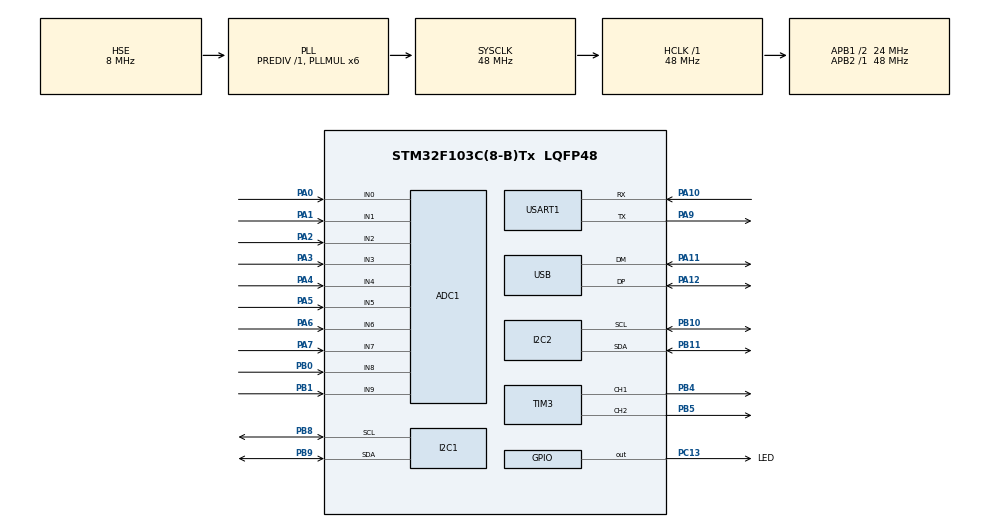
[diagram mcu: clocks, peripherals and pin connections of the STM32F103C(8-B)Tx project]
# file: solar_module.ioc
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ADC1.Channel-0\#ChannelRegularConversion=ADC_CHANNEL_0
ADC1.Channel-2\#ChannelRegularConversion=ADC_CHANNEL_1
ADC1.ContinuousConvMode=DISABLE
ADC1.DataAlign=ADC_DATAALIGN_RIGHT
ADC1.DiscontinuousConvMode=DISABLE
ADC1.EnableAnalogWatchDog=false
ADC1.EnableRegularConversion=ENABLE
ADC1.ExternalTrigConv=ADC_SOFTWARE_START
ADC1.InjNumberOfConversion=0
ADC1.NbrOfConversion=2
ADC1.NbrOfConversionFlag=1
ADC1.Rank-0\#ChannelRegularConversion=1
ADC1.Rank-2\#ChannelRegularConversion=2
ADC1.SamplingTime-0\#ChannelRegularConversion=ADC_SAMPLETIME_55CYCLES_5
ADC1.SamplingTime-2\#ChannelRegularConversion=ADC_SAMPLETIME_55CYCLES_5
ADC1.ScanConvMode=ADC_SCAN_ENABLE
ADC1.master=1
Dma.ADC1.0.Direction=DMA_PERIPH_TO_MEMORY
Dma.ADC1.0.Instance=DMA1_Channel1
Dma.ADC1.0.MemDataAlignment=DMA_MDATAALIGN_HALFWORD
Dma.ADC1.0.MemInc=DMA_MINC_ENABLE
Dma.ADC1.0.Mode=DMA_NORMAL
Dma.ADC1.0.PeriphDataAlignment=DMA_PDATAALIGN_HALFWORD
Dma.ADC1.0.PeriphInc=DMA_PINC_DISABLE
Dma.ADC1.0.Priority=DMA_PRIORITY_LOW
Dma.Request0=ADC1
Mcu.Family=STM32F1
Mcu.Name=STM32F103C(8-B)Tx
Mcu.Package=LQFP48
NVIC.DMA1_Channel1_IRQn=true\:0\:0\:false\:false\:true\:false
NVIC.PriorityGroup=NVIC_PRIORITYGROUP_4
NVIC.USB_LP_CAN1_RX0_IRQn=true\:0\:0\:false\:false\:true\:false
PA0-WKUP.Signal=ADCx_IN0
PA1.Signal=ADCx_IN1
PA10.Mode=Asynchronous
PA10.Signal=USART1_RX
PA11.Mode=Device
PA11.Signal=USB_DM
PA12.Mode=Device
PA12.Signal=USB_DP
PA13.Mode=Serial_Wire
PA13.Signal=SYS_JTMS-SWDIO
PA14.Mode=Serial_Wire
PA14.Signal=SYS_JTCK-SWCLK
PA2.Signal=ADCx_IN2
PA3.Signal=ADCx_IN3
PA4.Signal=ADCx_IN4
PA5.Signal=ADCx_IN5
PA6.Signal=ADCx_IN6
PA7.Signal=ADCx_IN7
PA9.Mode=Asynchronous
PA9.Signal=USART1_TX
PB0.Signal=ADCx_IN8
PB1.Signal=ADCx_IN9
PB10.Mode=I2C
PB10.Signal=I2C2_SCL
PB11.Mode=I2C
PB11.Signal=I2C2_SDA
PB4.Signal=S_TIM3_CH1
PB5.Signal=S_TIM3_CH2
PB8.Mode=I2C
PB8.Signal=I2C1_SCL
PB9.Mode=I2C
PB9.Signal=I2C1_SDA
PC13-TAMPER-RTC.GPIO_Label=LED
PC13-TAMPER-RTC.GPIO_ModeDefaultOutputPP=GPIO_MODE_OUTPUT_PP
PC13-TAMPER-RTC.GPIO_Speed=GPIO_SPEED_FREQ_LOW
PC13-TAMPER-RTC.PinState=GPIO_PIN_RESET
PC13-TAMPER-RTC.Signal=GPIO_Output
PD0-OSC_IN.Mode=HSE-External-Oscillator
PD0-OSC_IN.Signal=RCC_OSC_IN
PD1-OSC_OUT.Mode=HSE-External-Oscillator
PD1-OSC_OUT.Signal=RCC_OSC_OUT
ProjectManager.HeapSize=0x200
ProjectManager.StackSize=0x400
ProjectManager.TargetToolchain=TrueSTUDIO
RCC.ADCPresc=RCC_ADCPCLK2_DIV4
RCC.AHBFreq_Value=48000000
RCC.APB1CLKDivider=RCC_HCLK_DIV2
RCC.APB1Freq_Value=24000000
RCC.APB1TimFreq_Value=48000000
RCC.APB2Freq_Value=48000000
RCC.APB2TimFreq_Value=48000000
RCC.HCLKFreq_Value=48000000
RCC.PLLMUL=RCC_PLL_MUL6
RCC.PLLSourceVirtual=RCC_PLLSOURCE_HSE
RCC.SYSCLKFreq_VALUE=48000000
RCC.SYSCLKSource=RCC_SYSCLKSOURCE_PLLCLK
RCC.USBFreq_Value=48000000
SH.ADCx_IN0.0=ADC1_IN0,IN0
SH.ADCx_IN1.0=ADC1_IN1,IN1
SH.ADCx_IN2.0=ADC1_IN2,IN2
SH.ADCx_IN3.0=ADC1_IN3,IN3
SH.ADCx_IN4.0=ADC1_IN4,IN4
SH.ADCx_IN5.0=ADC1_IN5,IN5
SH.ADCx_IN6.0=ADC1_IN6,IN6
SH.ADCx_IN7.0=ADC1_IN7,IN7
SH.ADCx_IN8.0=ADC1_IN8,IN8
SH.ADCx_IN9.0=ADC1_IN9,IN9
SH.S_TIM3_CH1.0=TIM3_CH1,PWM Generation1 CH1
SH.S_TIM3_CH2.0=TIM3_CH2,PWM Generation2 CH2
TIM3.Channel-PWM\ Generation1\ CH1=TIM_CHANNEL_1
TIM3.Channel-PWM\ Generation2\ CH2=TIM_CHANNEL_2
USART1.VirtualMode=VM_ASYNC
USB.ep0_mps=DEP0CTL_MPS_64
USB_DEVICE.CLASS_NAME_FS=CDC
USB_DEVICE.VirtualMode=Cdc
USB_DEVICE.VirtualModeFS=Cdc_FS
VP_USB_DEVICE_VS_USB_DEVICE_CDC_FS.Mode=CDC_FS
board=solar_module

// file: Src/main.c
/**
  ******************************************************************************
  * @file           : main.c
  * @brief          : Main program body
  ******************************************************************************
  * This notice applies to any and all portions of this file
  * that are not between comment pairs USER CODE BEGIN and
  * USER CODE END. Other portions of this file, whether
  * inserted by the user or by software development tools
  * are owned by their respective copyright owners.
  *
  * Copyright (c) 2018 STMicroelectronics International N.V.
  * All rights reserved.
  *
  * Redistribution and use in source and binary forms, with or without
  * modification, are permitted, provided that the following conditions are met:
  *
  * 1. Redistribution of source code must retain the above copyright notice,
  *    this list of conditions and the following disclaimer.
  * 2. Redistributions in binary form must reproduce the above copyright notice,
  *    this list of conditions and the following disclaimer in the documentation
  *    and/or other materials provided with the distribution.
  * 3. Neither the name of STMicroelectronics nor the names of other
  *    contributors to this software may be used to endorse or promote products
  *    derived from this software without specific written permission.
  * 4. This software, including modifications and/or derivative works of this
  *    software, must execute solely and exclusively on microcontroller or
  *    microprocessor devices manufactured by or for STMicroelectronics.
  * 5. Redistribution and use of this software other than as permitted under
  *    this license is void and will automatically terminate your rights under
  *    this license.
  *
  * THIS SOFTWARE IS PROVIDED BY STMICROELECTRONICS AND CONTRIBUTORS "AS IS"
  * AND ANY EXPRESS, IMPLIED OR STATUTORY WARRANTIES, INCLUDING, BUT NOT
  * LIMITED TO, THE IMPLIED WARRANTIES OF MERCHANTABILITY, FITNESS FOR A
  * PARTICULAR PURPOSE AND NON-INFRINGEMENT OF THIRD PARTY INTELLECTUAL PROPERTY
  * RIGHTS ARE DISCLAIMED TO THE FULLEST EXTENT PERMITTED BY LAW. IN NO EVENT
  * SHALL STMICROELECTRONICS OR CONTRIBUTORS BE LIABLE FOR ANY DIRECT, INDIRECT,
  * INCIDENTAL, SPECIAL, EXEMPLARY, OR CONSEQUENTIAL DAMAGES (INCLUDING, BUT NOT
  * LIMITED TO, PROCUREMENT OF SUBSTITUTE GOODS OR SERVICES; LOSS OF USE, DATA,
  * OR PROFITS; OR BUSINESS INTERRUPTION) HOWEVER CAUSED AND ON ANY THEORY OF
  * LIABILITY, WHETHER IN CONTRACT, STRICT LIABILITY, OR TORT (INCLUDING
  * NEGLIGENCE OR OTHERWISE) ARISING IN ANY WAY OUT OF THE USE OF THIS SOFTWARE,
  * EVEN IF ADVISED OF THE POSSIBILITY OF SUCH DAMAGE.
  *
  ******************************************************************************
  */
#include "main.h"
#include "stm32f1xx_hal.h"
#include "usb_device.h"

/* USER CODE BEGIN Includes */
#include "usbd_cdc_if.h"
/* USER CODE END Includes */

ADC_HandleTypeDef hadc1;
DMA_HandleTypeDef hdma_adc1;

I2C_HandleTypeDef hi2c1;
I2C_HandleTypeDef hi2c2;

TIM_HandleTypeDef htim3;

UART_HandleTypeDef huart1;

/* USER CODE BEGIN PV */
/* Private variables ---------------------------------------------------------*/
volatile int numcalls = 0;

/* USER CODE END PV */

void SystemClock_Config(void);
static void MX_GPIO_Init(void);
static void MX_DMA_Init(void);
static void MX_ADC1_Init(void);
static void MX_I2C1_Init(void);
static void MX_I2C2_Init(void);
static void MX_TIM3_Init(void);
static void MX_USART1_UART_Init(void);

void HAL_TIM_MspPostInit(TIM_HandleTypeDef *htim);

/* USER CODE BEGIN PFP */
/* Private function prototypes -----------------------------------------------*/

/* USER CODE END PFP */

int main(void)
{

  /* MCU Configuration----------------------------------------------------------*/

  /* Reset of all peripherals, Initializes the Flash interface and the Systick. */
  HAL_Init();

  /* Configure the system clock */
  SystemClock_Config();

  /* Initialize all configured peripherals */
  MX_GPIO_Init();
  MX_DMA_Init();
  MX_ADC1_Init();
  MX_I2C1_Init();
  MX_I2C2_Init();
  MX_TIM3_Init();
  MX_USART1_UART_Init();
  MX_USB_DEVICE_Init();
  /* USER CODE BEGIN 2 */
  uint8_t buf[100];
  int16_t dma_buffer[2];
  /* USER CODE END 2 */

  /* Infinite loop */
  /* USER CODE BEGIN WHILE */
  while (1)
  {
	  int len = sprintf((char*)buf, "Interrupts: %i\tADC0: %i\tADC1: %i\n", numcalls, dma_buffer[0], dma_buffer[1]);
	  CDC_Transmit_FS(buf, len);
	  HAL_GPIO_TogglePin(LED_GPIO_Port, LED_Pin);
	  numcalls = 0;
	  HAL_ADC_Start_DMA(&hadc1, (uint32_t*)dma_buffer, 2);
	  HAL_Delay(1000);
  /* USER CODE END WHILE */

  }

}

void SystemClock_Config(void)
{

  RCC_OscInitTypeDef RCC_OscInitStruct;
  RCC_ClkInitTypeDef RCC_ClkInitStruct;
  RCC_PeriphCLKInitTypeDef PeriphClkInit;

    /**Initializes the CPU, AHB and APB busses clocks
    */
  RCC_OscInitStruct.OscillatorType = RCC_OSCILLATORTYPE_HSE;
  RCC_OscInitStruct.HSEState = RCC_HSE_ON;
  RCC_OscInitStruct.HSEPredivValue = RCC_HSE_PREDIV_DIV1;
  RCC_OscInitStruct.HSIState = RCC_HSI_ON;
  RCC_OscInitStruct.PLL.PLLState = RCC_PLL_ON;
  RCC_OscInitStruct.PLL.PLLSource = RCC_PLLSOURCE_HSE;
  RCC_OscInitStruct.PLL.PLLMUL = RCC_PLL_MUL6;
  if (HAL_RCC_OscConfig(&RCC_OscInitStruct) != HAL_OK)
  {
    _Error_Handler(__FILE__, __LINE__);
  }

    /**Initializes the CPU, AHB and APB busses clocks
    */
  RCC_ClkInitStruct.ClockType = RCC_CLOCKTYPE_HCLK|RCC_CLOCKTYPE_SYSCLK
                              |RCC_CLOCKTYPE_PCLK1|RCC_CLOCKTYPE_PCLK2;
  RCC_ClkInitStruct.SYSCLKSource = RCC_SYSCLKSOURCE_PLLCLK;
  RCC_ClkInitStruct.AHBCLKDivider = RCC_SYSCLK_DIV1;
  RCC_ClkInitStruct.APB1CLKDivider = RCC_HCLK_DIV2;
  RCC_ClkInitStruct.APB2CLKDivider = RCC_HCLK_DIV1;

  if (HAL_RCC_ClockConfig(&RCC_ClkInitStruct, FLASH_LATENCY_1) != HAL_OK)
  {
    _Error_Handler(__FILE__, __LINE__);
  }

  PeriphClkInit.PeriphClockSelection = RCC_PERIPHCLK_ADC|RCC_PERIPHCLK_USB;
  PeriphClkInit.AdcClockSelection = RCC_ADCPCLK2_DIV4;
  PeriphClkInit.UsbClockSelection = RCC_USBCLKSOURCE_PLL;
  if (HAL_RCCEx_PeriphCLKConfig(&PeriphClkInit) != HAL_OK)
  {
    _Error_Handler(__FILE__, __LINE__);
  }

    /**Configure the Systick interrupt time
    */
  HAL_SYSTICK_Config(HAL_RCC_GetHCLKFreq()/1000);

    /**Configure the Systick
    */
  HAL_SYSTICK_CLKSourceConfig(SYSTICK_CLKSOURCE_HCLK);

  /* SysTick_IRQn interrupt configuration */
  HAL_NVIC_SetPriority(SysTick_IRQn, 0, 0);
}

/* ADC1 init function */
static void MX_ADC1_Init(void)
{

  ADC_ChannelConfTypeDef sConfig;

    /**Common config
    */
  hadc1.Instance = ADC1;
  hadc1.Init.ScanConvMode = ADC_SCAN_ENABLE;
  hadc1.Init.ContinuousConvMode = DISABLE;
  hadc1.Init.DiscontinuousConvMode = DISABLE;
  hadc1.Init.ExternalTrigConv = ADC_SOFTWARE_START;
  hadc1.Init.DataAlign = ADC_DATAALIGN_RIGHT;
  hadc1.Init.NbrOfConversion = 2;
  if (HAL_ADC_Init(&hadc1) != HAL_OK)
  {
    _Error_Handler(__FILE__, __LINE__);
  }

    /**Configure Regular Channel
    */
  sConfig.Channel = ADC_CHANNEL_0;
  sConfig.Rank = ADC_REGULAR_RANK_1;
  sConfig.SamplingTime = ADC_SAMPLETIME_55CYCLES_5;
  if (HAL_ADC_ConfigChannel(&hadc1, &sConfig) != HAL_OK)
  {
    _Error_Handler(__FILE__, __LINE__);
  }

    /**Configure Regular Channel
    */
  sConfig.Channel = ADC_CHANNEL_1;
  sConfig.Rank = ADC_REGULAR_RANK_2;
  if (HAL_ADC_ConfigChannel(&hadc1, &sConfig) != HAL_OK)
  {
    _Error_Handler(__FILE__, __LINE__);
  }

}

/* I2C1 init function */
static void MX_I2C1_Init(void)
{

  hi2c1.Instance = I2C1;
  hi2c1.Init.ClockSpeed = 100000;
  hi2c1.Init.DutyCycle = I2C_DUTYCYCLE_2;
  hi2c1.Init.OwnAddress1 = 0;
  hi2c1.Init.AddressingMode = I2C_ADDRESSINGMODE_7BIT;
  hi2c1.Init.DualAddressMode = I2C_DUALADDRESS_DISABLE;
  hi2c1.Init.OwnAddress2 = 0;
  hi2c1.Init.GeneralCallMode = I2C_GENERALCALL_DISABLE;
  hi2c1.Init.NoStretchMode = I2C_NOSTRETCH_DISABLE;
  if (HAL_I2C_Init(&hi2c1) != HAL_OK)
  {
    _Error_Handler(__FILE__, __LINE__);
  }

}

/* I2C2 init function */
static void MX_I2C2_Init(void)
{

  hi2c2.Instance = I2C2;
  hi2c2.Init.ClockSpeed = 100000;
  hi2c2.Init.DutyCycle = I2C_DUTYCYCLE_2;
  hi2c2.Init.OwnAddress1 = 0;
  hi2c2.Init.AddressingMode = I2C_ADDRESSINGMODE_7BIT;
  hi2c2.Init.DualAddressMode = I2C_DUALADDRESS_DISABLE;
  hi2c2.Init.OwnAddress2 = 0;
  hi2c2.Init.GeneralCallMode = I2C_GENERALCALL_DISABLE;
  hi2c2.Init.NoStretchMode = I2C_NOSTRETCH_DISABLE;
  if (HAL_I2C_Init(&hi2c2) != HAL_OK)
  {
    _Error_Handler(__FILE__, __LINE__);
  }

}

/* TIM3 init function */
static void MX_TIM3_Init(void)
{

  TIM_MasterConfigTypeDef sMasterConfig;
  TIM_OC_InitTypeDef sConfigOC;

  htim3.Instance = TIM3;
  htim3.Init.Prescaler = 0;
  htim3.Init.CounterMode = TIM_COUNTERMODE_UP;
  htim3.Init.Period = 0;
  htim3.Init.ClockDivision = TIM_CLOCKDIVISION_DIV1;
  htim3.Init.AutoReloadPreload = TIM_AUTORELOAD_PRELOAD_DISABLE;
  if (HAL_TIM_PWM_Init(&htim3) != HAL_OK)
  {
    _Error_Handler(__FILE__, __LINE__);
  }

  sMasterConfig.MasterOutputTrigger = TIM_TRGO_RESET;
  sMasterConfig.MasterSlaveMode = TIM_MASTERSLAVEMODE_DISABLE;
  if (HAL_TIMEx_MasterConfigSynchronization(&htim3, &sMasterConfig) != HAL_OK)
  {
    _Error_Handler(__FILE__, __LINE__);
  }

  sConfigOC.OCMode = TIM_OCMODE_PWM1;
  sConfigOC.Pulse = 0;
  sConfigOC.OCPolarity = TIM_OCPOLARITY_HIGH;
  sConfigOC.OCFastMode = TIM_OCFAST_DISABLE;
  if (HAL_TIM_PWM_ConfigChannel(&htim3, &sConfigOC, TIM_CHANNEL_1) != HAL_OK)
  {
    _Error_Handler(__FILE__, __LINE__);
  }

  if (HAL_TIM_PWM_ConfigChannel(&htim3, &sConfigOC, TIM_CHANNEL_2) != HAL_OK)
  {
    _Error_Handler(__FILE__, __LINE__);
  }

  HAL_TIM_MspPostInit(&htim3);

}

/* USART1 init function */
static void MX_USART1_UART_Init(void)
{

  huart1.Instance = USART1;
  huart1.Init.BaudRate = 115200;
  huart1.Init.WordLength = UART_WORDLENGTH_8B;
  huart1.Init.StopBits = UART_STOPBITS_1;
  huart1.Init.Parity = UART_PARITY_NONE;
  huart1.Init.Mode = UART_MODE_TX_RX;
  huart1.Init.HwFlowCtl = UART_HWCONTROL_NONE;
  huart1.Init.OverSampling = UART_OVERSAMPLING_16;
  if (HAL_UART_Init(&huart1) != HAL_OK)
  {
    _Error_Handler(__FILE__, __LINE__);
  }

}

static void MX_DMA_Init(void)
{
  /* DMA controller clock enable */
  __HAL_RCC_DMA1_CLK_ENABLE();

  /* DMA interrupt init */
  /* DMA1_Channel1_IRQn interrupt configuration */
  HAL_NVIC_SetPriority(DMA1_Channel1_IRQn, 0, 0);
  HAL_NVIC_EnableIRQ(DMA1_Channel1_IRQn);

}

/** Configure pins as
        * Analog
        * Input
        * Output
        * EVENT_OUT
        * EXTI
*/
static void MX_GPIO_Init(void)
{

  GPIO_InitTypeDef GPIO_InitStruct;

  /* GPIO Ports Clock Enable */
  __HAL_RCC_GPIOC_CLK_ENABLE();
  __HAL_RCC_GPIOD_CLK_ENABLE();
  __HAL_RCC_GPIOA_CLK_ENABLE();
  __HAL_RCC_GPIOB_CLK_ENABLE();

  /*Configure GPIO pin Output Level */
  HAL_GPIO_WritePin(LED_GPIO_Port, LED_Pin, GPIO_PIN_RESET);

  /*Configure GPIO pin : LED_Pin */
  GPIO_InitStruct.Pin = LED_Pin;
  GPIO_InitStruct.Mode = GPIO_MODE_OUTPUT_PP;
  GPIO_InitStruct.Speed = GPIO_SPEED_FREQ_LOW;
  HAL_GPIO_Init(LED_GPIO_Port, &GPIO_InitStruct);

}

/* USER CODE BEGIN 4 */
void HAL_ADC_ConvCpltCallback(ADC_HandleTypeDef* hadc)
{
	numcalls++;
}
/* USER CODE END 4 */

void _Error_Handler(char *file, int line)
{
  while(1)
  {
  }
}

/************************ (C) COPYRIGHT STMicroelectronics *****END OF FILE****/
